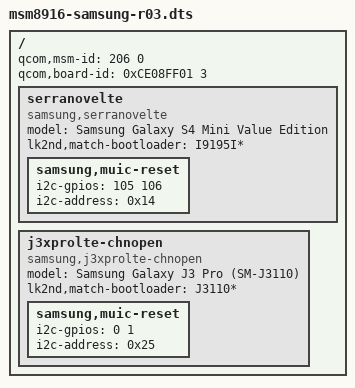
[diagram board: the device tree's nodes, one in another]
// SPDX-License-Identifier: GPL-2.0-only

/dts-v1/;

/include/ "msm8916.dtsi"

/ {
	// This is used by the bootloader to find the correct DTB
	qcom,msm-id = <206 0>;
	qcom,board-id = <0xCE08FF01 3>;

	serranovelte {
		model = "Samsung Galaxy S4 Mini Value Edition";
		compatible = "samsung,serranovelte", "qcom,msm8916", "lk2nd,device";
		lk2nd,match-bootloader = "I9195I*";

		samsung,muic-reset {
			i2c-gpios = <105 106>;
			i2c-address = <0x14>;
		};
	};

	j3xprolte-chnopen {
		model = "Samsung Galaxy J3 Pro (SM-J3110)";
		compatible = "samsung,j3xprolte-chnopen", "qcom,msm8916", "lk2nd,device";
		lk2nd,match-bootloader = "J3110*";
		samsung,muic-reset {
			i2c-gpios = <0 1>;
			i2c-address = <0x25>;
		};
	};
};
